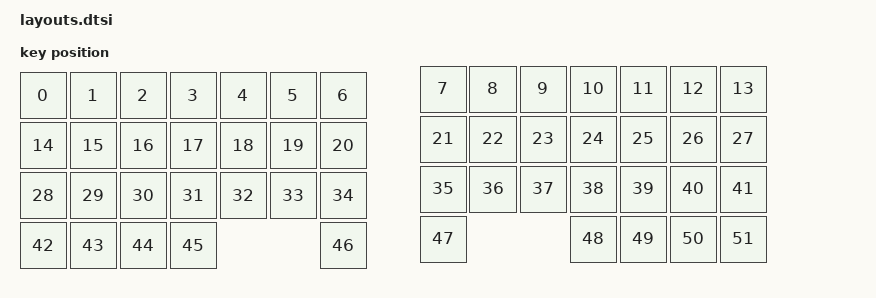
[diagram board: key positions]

#include <physical_layouts.dtsi>
/ {
    physical_layout0: physical_layout0 {
        compatible = "zmk,physical-layout";
        display-name = "Layout";
        keys
            = <&key_physical_attrs 100 100 (-50) 63 0 0 0>
			,<&key_physical_attrs 100 100 50 63 0 0 0>
			,<&key_physical_attrs 100 100 150 63 0 0 0>
			,<&key_physical_attrs 100 100 250 63 0 0 0>
			,<&key_physical_attrs 100 100 350 63 0 0 0>
			,<&key_physical_attrs 100 100 450 63 0 0 0>
			,<&key_physical_attrs 100 100 550 63 0 0 0>
			,<&key_physical_attrs 100 100 750 50 0 0 0>
			,<&key_physical_attrs 100 100 850 50 0 0 0>
			,<&key_physical_attrs 100 100 950 50 0 0 0>
			,<&key_physical_attrs 100 100 1050 50 0 0 0>
			,<&key_physical_attrs 100 100 1150 50 0 0 0>
			,<&key_physical_attrs 100 100 1250 50 0 0 0>
			,<&key_physical_attrs 100 100 1350 50 0 0 0>
			,<&key_physical_attrs 100 100 (-50) 163 0 0 0>
			,<&key_physical_attrs 100 100 50 163 0 0 0>
			,<&key_physical_attrs 100 100 150 163 0 0 0>
			,<&key_physical_attrs 100 100 250 163 0 0 0>
			,<&key_physical_attrs 100 100 350 163 0 0 0>
			,<&key_physical_attrs 100 100 450 163 0 0 0>
			,<&key_physical_attrs 100 100 550 163 0 0 0>
			,<&key_physical_attrs 100 100 750 150 0 0 0>
			,<&key_physical_attrs 100 100 850 150 0 0 0>
			,<&key_physical_attrs 100 100 950 150 0 0 0>
			,<&key_physical_attrs 100 100 1050 150 0 0 0>
			,<&key_physical_attrs 100 100 1150 150 0 0 0>
			,<&key_physical_attrs 100 100 1250 150 0 0 0>
			,<&key_physical_attrs 100 100 1350 150 0 0 0>
			,<&key_physical_attrs 100 100 (-50) 263 0 0 0>
			,<&key_physical_attrs 100 100 50 263 0 0 0>
			,<&key_physical_attrs 100 100 150 263 0 0 0>
			,<&key_physical_attrs 100 100 250 263 0 0 0>
			,<&key_physical_attrs 100 100 350 263 0 0 0>
			,<&key_physical_attrs 100 100 450 263 0 0 0>
			,<&key_physical_attrs 100 100 550 263 0 0 0>
			,<&key_physical_attrs 100 100 750 250 0 0 0>
			,<&key_physical_attrs 100 100 850 250 0 0 0>
			,<&key_physical_attrs 100 100 950 250 0 0 0>
			,<&key_physical_attrs 100 100 1050 250 0 0 0>
			,<&key_physical_attrs 100 100 1150 250 0 0 0>
			,<&key_physical_attrs 100 100 1250 250 0 0 0>
			,<&key_physical_attrs 100 100 1350 250 0 0 0>
			,<&key_physical_attrs 100 100 (-50) 363 0 0 0>
			,<&key_physical_attrs 100 100 50 363 0 0 0>
			,<&key_physical_attrs 100 100 150 363 0 0 0>
			,<&key_physical_attrs 100 100 250 363 0 0 0>
			,<&key_physical_attrs 100 100 550 363 0 0 0>
			,<&key_physical_attrs 100 100 750 350 0 0 0>
			,<&key_physical_attrs 100 100 1050 350 0 0 0>
			,<&key_physical_attrs 100 100 1150 350 0 0 0>
			,<&key_physical_attrs 100 100 1250 350 0 0 0>
			,<&key_physical_attrs 100 100 1350 350 0 0 0>
            ;
    };
};
    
